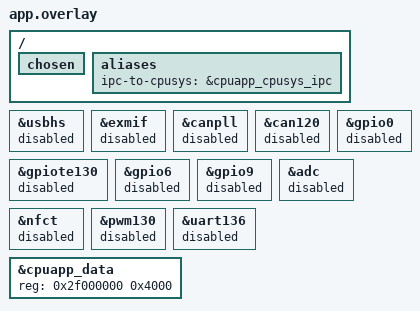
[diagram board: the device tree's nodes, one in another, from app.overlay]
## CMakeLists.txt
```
# Copyright (c) 2025 Nordic Semiconductor
# SPDX-License-Identifier: LicenseRef-Nordic-5-Clause

cmake_minimum_required(VERSION 3.20.0)

find_package(Zephyr REQUIRED HINTS $ENV{ZEPHYR_BASE})
project(empty_app_core)

# NORDIC SDK APP START
target_sources(app PRIVATE src/main.c)
# NORDIC SDK APP END
```

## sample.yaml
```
sample:
  description: Minimal sample used to boot radiocore
  name: Empty firmware for application core (nRF54H20)
tests:
  sample.nrf54h20.empty_app_core.build:
    build_only: true
    integration_platforms:
      - nrf54h20dk/nrf54h20/cpuapp
    platform_allow:
      - nrf54h20dk/nrf54h20/cpuapp
    tags:
      - ci_build
      - ci_samples_nrf54h20
```

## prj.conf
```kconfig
# Copyright (c) 2025 Nordic Semiconductor
# SPDX-License-Identifier: LicenseRef-Nordic-5-Clause

# Start radiocore and suspend app core
CONFIG_SOC_NRF54H20_CPURAD_ENABLE=y
CONFIG_PM=y

# Minimal configuration
CONFIG_SIZE_OPTIMIZATIONS=y
# Ineffective here: unsatisfied dependency (!CODE_DATA_RELOCATION), so LTO stays n.
# CONFIG_LTO=y
CONFIG_ISR_TABLES_LOCAL_DECLARATION=y
CONFIG_NUM_PREEMPT_PRIORITIES=0
CONFIG_THREAD_STACK_INFO=n
CONFIG_KERNEL_MEM_POOL=n
CONFIG_COMMON_LIBC_MALLOC=n
CONFIG_ARM_MPU=n
CONFIG_BUILTIN_STACK_GUARD=n
CONFIG_GPIO=n
CONFIG_PINCTRL=n
CONFIG_SERIAL=n
CONFIG_CONSOLE=n
CONFIG_EARLY_CONSOLE=n
CONFIG_STDOUT_CONSOLE=n
CONFIG_UART_CONSOLE=n
CONFIG_BOOT_BANNER=n
CONFIG_NCS_BOOT_BANNER=n
CONFIG_PRINTK=n
```

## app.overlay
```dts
/*
 * Copyright (c) 2025 Nordic Semiconductor ASA
 * SPDX-License-Identifier: LicenseRef-Nordic-5-Clause
 */

/* Disable some of the default nRF54H20 DK configuration.
 *
 * Ideally, doing this shouldn't be needed, but it prevents unused resources
 * from being included in the autogenerated UICR.PERIPHCONF.
 */

/ {
	/delete-node/ aliases;
	/delete-node/ buttons;
	/delete-node/ leds;
	/delete-node/ pwmleds;

	chosen {
		/delete-property/ zephyr,serial;
	};

	aliases {
		/* Required by NRFS_LOCAL_DOMAIN */
		ipc-to-cpusys = &cpuapp_cpusys_ipc;
	};
};

&usbhs {
	status = "disabled";
};

&exmif {
	status = "disabled";
};

&canpll {
	status = "disabled";
};

&can120 {
	status = "disabled";
};

&gpiote130 {
	status = "disabled";
	/delete-property/ owned-channels;
};

&gpio0 {
	status = "disabled";
};

&gpio6 {
	status = "disabled";
};

&gpio9 {
	status = "disabled";
};

&adc {
	status = "disabled";
};

&nfct {
	status = "disabled";
};

&pwm130 {
	status = "disabled";
};

&uart136 {
	status = "disabled";
};

/* Shrink cpuapp_data so unused Global RAM blocks can be powered off.
 * Must match the application memory_map cpuapp_data sizing.
 */
&cpuapp_data {
	reg = <0x2f000000 0x4000>;
};
```

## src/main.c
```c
/*
 * Copyright (c) 2025 Nordic Semiconductor ASA
 * SPDX-License-Identifier: LicenseRef-Nordic-5-Clause
 */

int main(void)
{
	return 0;
}
```
